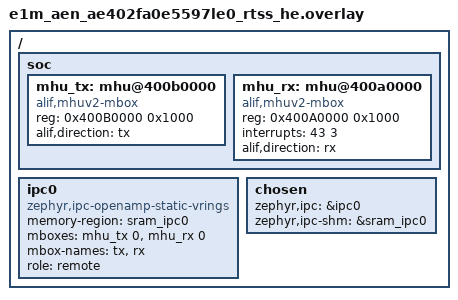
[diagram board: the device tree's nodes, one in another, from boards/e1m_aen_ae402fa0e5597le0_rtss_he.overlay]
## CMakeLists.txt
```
#
# Copyright 2026 Alp Lab AB
#
# SPDX-License-Identifier: Apache-2.0
#
# dualcore_he -- IPC-service RPMsg REMOTE demo for the rtss_he cluster of the
# Alp Lab E1M-AEN SoM. Its counterpart, dualcore_hp, is the RPMsg HOST and
# lives in ../dualcore_hp. Build each independently and flash both to the
# board's split MRAM partitions (see boards/alp/e1m_aen for the layout).
#

cmake_minimum_required(VERSION 3.20.0)

find_package(Zephyr REQUIRED HINTS $ENV{ZEPHYR_BASE})
project(dualcore_he)

target_sources(app PRIVATE src/main.c)
```

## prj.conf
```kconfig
# dualcore_he -- RPMsg REMOTE (rtss_he cluster, console uart3 = E1M UART1, pads AG4/AH4).
#
# CONFIG_MBOX / CONFIG_MBOX_ALIF_MHUV2 wire in the out-of-tree alif_mhuv2
# module (modules/alif-mhuv2) that backs the mhu_tx/mhu_rx nodes.
# CONFIG_IPC_SERVICE + CONFIG_IPC_SERVICE_BACKEND_RPMSG select the RPMsg
# static-vrings backend, matching the "zephyr,ipc-openamp-static-vrings"
# ipc0 node in the board overlay. CONFIG_OPENAMP is the backend's own
# dependency (see zephyr/samples/subsys/ipc/ipc_service/static_vrings/prj.conf).
CONFIG_MBOX=y
CONFIG_MBOX_ALIF_MHUV2=y
CONFIG_IPC_SERVICE=y
CONFIG_IPC_SERVICE_BACKEND_RPMSG=y
CONFIG_OPENAMP=y

CONFIG_LOG=y
CONFIG_LOG_MODE_IMMEDIATE=y

CONFIG_SERIAL=y
CONFIG_CONSOLE=y
CONFIG_UART_CONSOLE=y

CONFIG_MAIN_STACK_SIZE=2048
CONFIG_HEAP_MEM_POOL_SIZE=4096
```

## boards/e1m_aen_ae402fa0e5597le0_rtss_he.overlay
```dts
/*
 * Copyright 2026 Alp Lab AB
 *
 * SPDX-License-Identifier: Apache-2.0
 *
 * dualcore_he overlay for e1m_aen/ae402fa0e5597le0/rtss_he.
 *
 * mhu_tx / mhu_rx: the Alif MHUv2 mailbox pair this cluster uses to signal
 * the rtss_hp cluster. Each M55 core sees its own TX/RX frame at the SAME
 * register addresses (0x400B0000 / 0x400A0000) -- that is why this overlay
 * is byte-for-byte identical to the ae822fa0e5597ls0 one and to the mhu
 * nodes in dualcore_hp's overlays; only the ipc0 "role" property differs
 * between REMOTE (here) and HOST (dualcore_hp).
 *
 * interrupts = <43 3> on mhu_rx: GIC IRQ 43 / priority 3 for this MHUv2 RX
 * frame. Not re-derived here -- carried over verbatim from the canonical
 * hardware spec this project was built against; see modules/alif-mhuv2 for
 * the driver that consumes it.
 */

/ {
	soc {
		mhu_tx: mhu@400b0000 {
			compatible = "alif,mhuv2-mbox";
			reg = <0x400B0000 0x1000>;
			alif,direction = "tx";
			#mbox-cells = <1>;
			status = "okay";
		};

		mhu_rx: mhu@400a0000 {
			compatible = "alif,mhuv2-mbox";
			reg = <0x400A0000 0x1000>;
			interrupts = <43 3>;
			alif,direction = "rx";
			#mbox-cells = <1>;
			status = "okay";
		};
	};

	/*
	 * role = "remote": this is the rtss_he (secondary) side of the RPMsg
	 * link. The dualcore_hp overlays set role = "host" for the matching
	 * ipc0 node on rtss_hp. memory-region points at the sram_ipc0
	 * carve-out declared once in the board .dts (shared, non-cacheable
	 * SRAM0) -- same physical region both cores' overlays reference.
	 */
	ipc0: ipc0 {
		compatible = "zephyr,ipc-openamp-static-vrings";
		memory-region = <&sram_ipc0>;
		mboxes = <&mhu_tx 0>, <&mhu_rx 0>;
		mbox-names = "tx", "rx";
		role = "remote";
		status = "okay";
	};

	chosen {
		zephyr,ipc = &ipc0;
		zephyr,ipc-shm = &sram_ipc0;
	};
};
```

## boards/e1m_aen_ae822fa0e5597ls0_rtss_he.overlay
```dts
/*
 * Copyright 2026 Alp Lab AB
 *
 * SPDX-License-Identifier: Apache-2.0
 *
 * dualcore_he overlay for e1m_aen/ae822fa0e5597ls0/rtss_he.
 *
 * mhu_tx / mhu_rx: the Alif MHUv2 mailbox pair this cluster uses to signal
 * the rtss_hp cluster. Each M55 core sees its own TX/RX frame at the SAME
 * register addresses (0x400B0000 / 0x400A0000) -- that is why this overlay
 * is byte-for-byte identical to the ae402fa0e5597le0 one and to the mhu
 * nodes in dualcore_hp's overlays; only the ipc0 "role" property differs
 * between REMOTE (here) and HOST (dualcore_hp).
 *
 * interrupts = <43 3> on mhu_rx: GIC IRQ 43 / priority 3 for this MHUv2 RX
 * frame. Not re-derived here -- carried over verbatim from the canonical
 * hardware spec this project was built against; see modules/alif-mhuv2 for
 * the driver that consumes it.
 */

/ {
	soc {
		mhu_tx: mhu@400b0000 {
			compatible = "alif,mhuv2-mbox";
			reg = <0x400B0000 0x1000>;
			alif,direction = "tx";
			#mbox-cells = <1>;
			status = "okay";
		};

		mhu_rx: mhu@400a0000 {
			compatible = "alif,mhuv2-mbox";
			reg = <0x400A0000 0x1000>;
			interrupts = <43 3>;
			alif,direction = "rx";
			#mbox-cells = <1>;
			status = "okay";
		};
	};

	/*
	 * role = "remote": this is the rtss_he (secondary) side of the RPMsg
	 * link. The dualcore_hp overlays set role = "host" for the matching
	 * ipc0 node on rtss_hp. memory-region points at the sram_ipc0
	 * carve-out declared once in the board .dts (shared, non-cacheable
	 * SRAM0) -- same physical region both cores' overlays reference.
	 */
	ipc0: ipc0 {
		compatible = "zephyr,ipc-openamp-static-vrings";
		memory-region = <&sram_ipc0>;
		mboxes = <&mhu_tx 0>, <&mhu_rx 0>;
		mbox-names = "tx", "rx";
		role = "remote";
		status = "okay";
	};

	chosen {
		zephyr,ipc = &ipc0;
		zephyr,ipc-shm = &sram_ipc0;
	};
};
```

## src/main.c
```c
/*
 * Copyright 2026 Alp Lab AB
 *
 * SPDX-License-Identifier: Apache-2.0
 *
 * dualcore_he -- IPC-service RPMsg REMOTE demo, rtss_he cluster of the Alp
 * Lab E1M-AEN SoM (Alif Ensemble E4/E8, ae402fa0e5597le0 / ae822fa0e5597ls0).
 *
 * WHAT THIS DEMONSTRATES: the remote side of the dual-core RPMsg link built
 * in apps/dualcore_hp -- see that file's top-of-file comment for the full
 * picture (backend, mailbox driver, MRAM/board layout). This file is
 * intentionally the smaller half: it has no notion of demo cadence, it just
 * answers whatever the host sends.
 *
 * ROLE: this cluster is the RPMsg "remote" -- see the ipc0 node's
 * role = "remote" property in boards/e1m_aen_*_rtss_he.overlay. Its
 * counterpart is apps/dualcore_hp, the "host", running on the SAME
 * silicon's rtss_hp cluster out of the other half of the split MRAM.
 *
 * PROTOCOL: on every received struct ping_pong_msg (a PING), this thread
 * logs it and echoes the identical struct straight back as the PONG -- no
 * sequence-number bookkeeping of its own; the host owns the sequence and
 * detects gaps/reordering on its side.
 *
 * WHY THE SEND HAPPENS IN main()'S THREAD, NOT IN THE RECEIVED CALLBACK:
 * the RPMsg backend invokes .received from its own processing context, and
 * every upstream ipc_service sample (see
 * zephyr/samples/subsys/ipc/ipc_service/BACKEND/remote/src/main.c) defers the
 * reply to a separate thread woken by a semaphore rather than calling
 * ipc_service_send() straight out of that callback. This file follows the
 * same pattern.
 */

#include <string.h>

#include <zephyr/device.h>
#include <zephyr/devicetree.h>
#include <zephyr/ipc/ipc_service.h>
#include <zephyr/kernel.h>
#include <zephyr/logging/log.h>

LOG_MODULE_REGISTER(dualcore_he, LOG_LEVEL_INF);

/* Console node name (e.g. "uart@4901a000"), read straight off the
 * `zephyr,console` chosen node this board target picked -- NEVER a literal
 * UART/core name in this file. A previous version of this banner hardcoded
 * "uart3 (E1M UART1)", which is wrong the moment this image is built for a
 * different board target -- see docs/BENCH-DUALCORE.md for a concrete case:
 * on the bench-proven dual-core run this app's REMOTE logic executed on
 * RTSS-HP, not RTSS-HE.
 */
#define CONSOLE_NODE_NAME DT_NODE_FULL_NAME(DT_CHOSEN(zephyr_console))

/* How long to wait for the endpoint to bind before nagging the log. See
 * dualcore_hp/src/main.c for the identical rationale.
 */
#define BOUND_WAIT_S 5

/*
 * Wire format shared with apps/dualcore_hp/src/main.c -- both sides MUST
 * agree on this layout; see that file's comment for why it is duplicated
 * rather than shared via a common header.
 */
struct ping_pong_msg {
	uint32_t seq;
};

static K_SEM_DEFINE(bound_sem, 0, 1);
static K_SEM_DEFINE(ping_sem, 0, 1);

/* Written by ep_recv() (RPMsg backend's callback context), read by main()
 * only after ping_sem has been given.
 */
static struct ping_pong_msg ping_msg;

static void ep_bound(void *priv)
{
	ARG_UNUSED(priv);
	k_sem_give(&bound_sem);
}

static void ep_recv(const void *data, size_t len, void *priv)
{
	ARG_UNUSED(priv);

	if (len != sizeof(ping_msg)) {
		LOG_ERR("PING has unexpected length %zu (expected %zu); dropping", len, sizeof(ping_msg));
		return;
	}

	memcpy(&ping_msg, data, sizeof(ping_msg));
	k_sem_give(&ping_sem);
}

static struct ipc_ept_cfg ep_cfg = {
    .name = "dualcore_ping_pong",
    .cb =
        {
            .bound = ep_bound,
            .received = ep_recv,
        },
};

int main(void)
{
	const struct device *ipc0_instance;
	struct ipc_ept       ep;
	int                  ret;

	/* Banner: names this core and its console from the BUILD, never a
	 * literal -- CONFIG_BOARD_TARGET is Zephyr's own
	 * "<board>/<qualifiers>" string for whatever target this image was
	 * actually configured for, and CONSOLE_NODE_NAME is read off the
	 * `zephyr,console` chosen node above. A previous version of this
	 * banner hardcoded "rtss_he" and "uart3 (E1M UART1)", which lied the
	 * moment this image was built for (or run on, via a debugger, as on
	 * the bench-proven path -- see docs/BENCH-DUALCORE.md) a different
	 * target.
	 */
	LOG_INF("=== Alp Lab E1M-AEN dualcore demo -- REMOTE ===");
	LOG_INF("board target: %s, console: %s", CONFIG_BOARD_TARGET, CONSOLE_NODE_NAME);

	ipc0_instance = DEVICE_DT_GET(DT_NODELABEL(ipc0));

	/*
	 * Log BEFORE opening, because on the remote side this call does not
	 * return until the host is up. The RPMsg static-vrings backend runs
	 * ipc_rpmsg_init() in this thread; for a non-host role that reaches
	 * rpmsg_init_vdev() -> rpmsg_virtio_wait_remote_ready(), an infinite
	 * loop polling the shared-memory virtio status byte for DRIVER_OK and
	 * k_sleep()ing 1 ms per pass. Only the rtss_hp host ever writes
	 * DRIVER_OK. So with no host running, this app parks here forever --
	 * correct standalone behaviour, but indistinguishable from a hang
	 * unless we say so first. Confirmed on E1M-AEN801 silicon: the board
	 * printed the two banner lines and then nothing for 45 s, with the
	 * core healthy in the idle thread (IPSR=0, no fault, no bound-wait
	 * warnings -- because the nag loop further down is never reached).
	 */
	LOG_INF("opening ipc0 as RPMsg remote -- BLOCKS here until the rtss_hp "
	        "host signals virtio DRIVER_OK in shared memory");

	ret = ipc_service_open_instance(ipc0_instance);
	if (ret < 0 && ret != -EALREADY) {
		LOG_ERR("ipc_service_open_instance() failed: %d", ret);
		return ret;
	}

	LOG_INF("ipc0 open -- host is alive");

	ret = ipc_service_register_endpoint(ipc0_instance, &ep, &ep_cfg);
	if (ret < 0) {
		LOG_ERR("ipc_service_register_endpoint() failed: %d", ret);
		return ret;
	}

	/* The host may not have registered its endpoint yet -- nag every
	 * BOUND_WAIT_S rather than blocking silently.
	 */
	while (k_sem_take(&bound_sem, K_SECONDS(BOUND_WAIT_S)) != 0) {
		LOG_WRN("endpoint not bound after %d s -- still waiting for the "
		        "rtss_hp host to register its endpoint",
		        BOUND_WAIT_S);
	}
	LOG_INF("endpoint bound; waiting for PING");

	for (;;) {
		k_sem_take(&ping_sem, K_FOREVER);

		LOG_INF("PING seq=%u received; echoing PONG", ping_msg.seq);

		ret = ipc_service_send(&ep, &ping_msg, sizeof(ping_msg));
		if (ret < 0) {
			LOG_ERR("ipc_service_send() failed for PONG seq=%u: %d", ping_msg.seq, ret);
		}
	}
}
```
